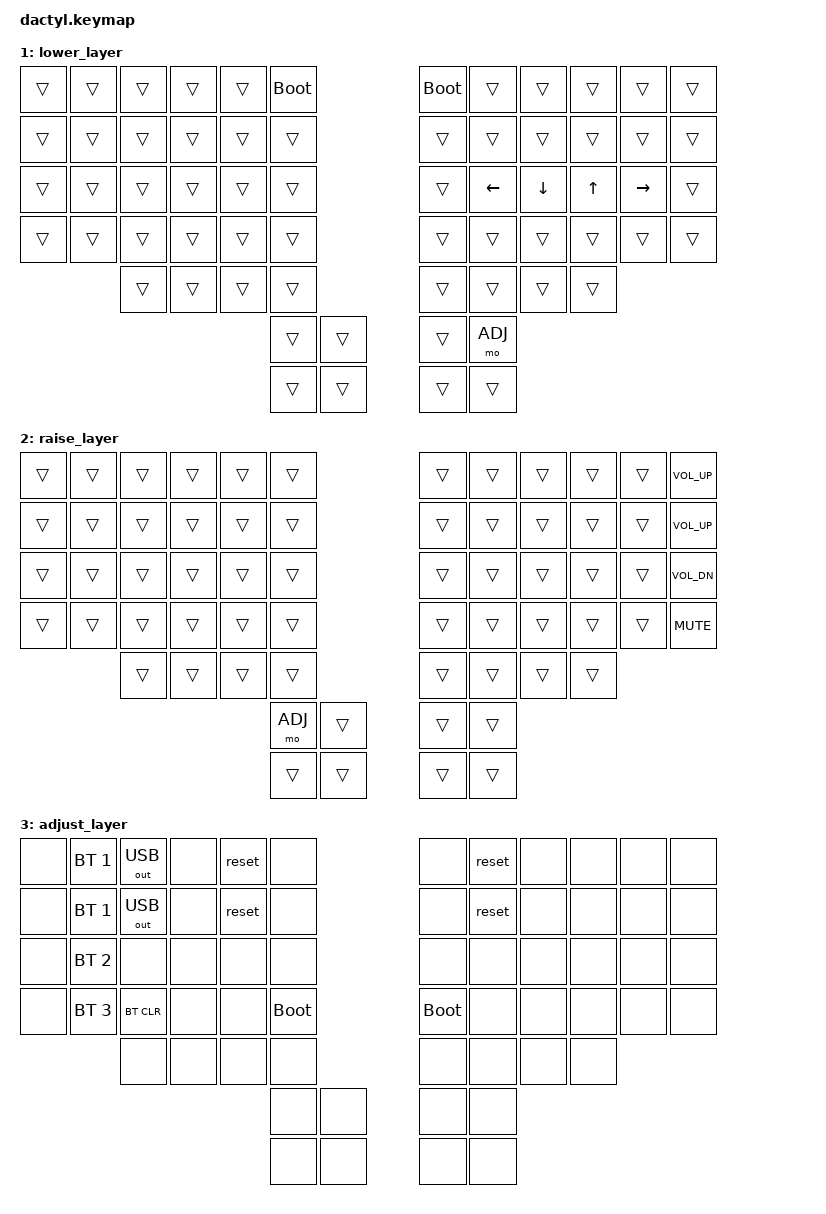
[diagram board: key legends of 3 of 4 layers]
#include <behaviors.dtsi>
#include <dt-bindings/zmk/keys.h>
#include <dt-bindings/zmk/bt.h>
#include <dt-bindings/zmk/outputs.h>

#define DEFAULT 0
#define LWR 1
#define RSE 2
#define ADJ 3

/ {
    keymap {
        compatible = "zmk,keymap";

        default_layer {
            bindings = <
                &kp ESC   &kp N1 &kp N2   &kp N3   &kp N4   &kp N5                            &kp N6 &kp N7 &kp N8    &kp N9  &kp N0   &kp BSPC
                &kp TAB   &kp Q  &kp W    &kp E    &kp R    &kp T                             &kp Y  &kp U  &kp I     &kp O   &kp P    &kp MINUS
                &kp LSHFT &kp A  &kp S    &kp D    &kp F    &kp G                             &kp H  &kp J  &kp K     &kp L   &kp SEMI &kp SQT
                &kp LCTRL &kp Z  &kp X    &kp C    &kp V    &kp B                             &kp N  &kp M  &kp COMMA &kp DOT &kp FSLH &kp BSLH
                                 &kp LBKT &kp RBKT &mo LWR  &kp SPACE                         &kp PLUS  &kp EQUAL
                                                            &kp RET  &mo RSE         &kp RET  &mo RSE
                                                            &kp HOME &kp DEL         &kp HOME &kp DEL
            >;
        };

        lower_layer {
            bindings = < 
                &trans  &trans &trans &trans &trans &bootloader                     &bootloader  &trans   &trans   &trans &trans    &trans
                &trans  &trans &trans &trans &trans &trans                                &trans &trans   &trans   &trans &trans    &trans
                &trans  &trans &trans &trans &trans &trans                                &trans &kp LEFT &kp DOWN &kp UP &kp RIGHT &trans
                &trans  &trans &trans &trans &trans &trans                                &trans &trans   &trans   &trans &trans    &trans
                               &trans &trans &trans &trans                                &trans &trans   &trans &trans
                                                    &trans &trans                  &trans &mo ADJ
                                                    &trans &trans                  &trans &trans
            >;
        };

        raise_layer {
            bindings = <
                &trans  &trans &trans &trans &trans &trans                              &trans &trans &trans &trans &trans &kp K_VOL_UP
                &trans  &trans &trans &trans &trans &trans                              &trans &trans &trans &trans &trans &kp K_VOL_UP
                &trans  &trans &trans &trans &trans &trans                              &trans &trans &trans &trans &trans &kp K_VOL_DN
                &trans  &trans &trans &trans &trans &trans                              &trans &trans &trans &trans &trans &kp K_MUTE
                               &trans &trans &trans &trans                              &trans &trans &trans &trans
                                                    &mo ADJ &trans               &trans &trans
                                                    &trans  &trans               &trans &trans
            >;
        };

        adjust_layer {
            bindings = <
                &none &bt BT_SEL 1 &out OUT_USB &none &reset &none                    &none       &reset &none &none &none &none
                &none &bt BT_SEL 1 &out OUT_USB &none &reset &none                    &none       &reset &none &none &none &none
                &none &bt BT_SEL 2 &none        &none &none  &none                    &none       &none  &none &none &none &none
                &none &bt BT_SEL 3 &bt BT_CLR   &none &none  &bootloader              &bootloader &none  &none &none &none &none
                                   &none        &none &none  &none                    &none       &none  &none &none
                                                             &none  &none       &none &none
                                                             &none  &none       &none &none
            >;
        };
    };
};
